# M462 register map
File version: 0.1
TOSHIBA Cortex-M3 MCU
Registers are 32-bit, read-write, reset 0x0 unless marked. A register's access mark holds for its fields unless they carry their own. Offsets are from the block's base; lines under a group give offsets from that group; [hi:lo] are bit positions; {n}, {i} and the like mark numbered series; 'fields as' and 'values as' point back to an identical list; <NAME> marks a mode.

## Memory map
0x40040000 SSP0 size 0x28 — Synchronous Serial Port
0x40041000 SSP1 size 0x28
0x40042000 SSP2 size 0x28
0x40048000 UART0 blocks up to offset 0x4C — UART
0x40049000 UART1 blocks up to offset 0x4C
0x4004C000 DMAA blocks up to offset 0x50 — DMA Controller
0x4004D000 DMAB blocks up to offset 0x50
0x4004E000 DMAC blocks up to offset 0x50
0x40050000 AD blocks up to offset 0x78 — 12bit A_D Converter
0x4005C000 EXB blocks up to offset 0x64 — External Bus Interface(EXB)
0x4005F000 DMAIF size 0xC — DMA Controller
0x40066000 ADILV blocks up to offset 0x24 — ADC infterface Register
0x400A0000 I2C0 size 0x1C — I2C Bus Interface (I2C)
0x400A1000 I2C1 size 0x1C
0x400A2000 I2C2 size 0x1C
0x400A3000 I2C3 size 0x1C
0x400A4000 I2C4 size 0x1C
0x400C4000 TB0 size 0x30 — 16-bit Timer_Event Counter (TB)
0x400C4100 TB1 size 0x30
0x400C4200 TB2 size 0x30
0x400C4300 TB3 size 0x30
0x400C4400 TB4 size 0x30
0x400C4500 TB5 size 0x30
0x400C4600 TB6 size 0x30
0x400C4700 TB7 size 0x30
0x400E1000 SC0 size 0x34 — Serial Channel (SC)
0x400E1100 SC1 size 0x34
0x400E1200 SC2 size 0x34
0x400E1600 SC6 size 0x34
0x400E1700 SC7 size 0x34
0x401C4800 TB8 size 0x30
0x401C4900 TB9 size 0x30
0x401C4A00 TBA size 0x30
0x401C4B00 TBB size 0x30
0x401C4C00 TBC size 0x30
0x401C4D00 TBD size 0x30
0x401C4E00 TBE size 0x30
0x401C4F00 TBF size 0x30
0x401E1300 SC3 size 0x34
0x401E1400 SC4 size 0x34
0x401E1500 SC5 size 0x34
0x401E1800 SC8 size 0x34
0x401E1900 SC9 size 0x34
0x402C0000 PA blocks up to offset 0x3C — Port A
0x402C0100 PB blocks up to offset 0x3C — Port B
0x402C0200 PC blocks up to offset 0x3C — Port C
0x402C0300 PD blocks up to offset 0x3C — Port D
0x402C0400 PE blocks up to offset 0x3C — Port E
0x402C0500 PF blocks up to offset 0x3C — Port F
0x402C0600 PG blocks up to offset 0x3C — Port G
0x402C0700 PH blocks up to offset 0x3C — Port H
0x402C0800 PJ blocks up to offset 0x3C — Port J
0x402C0900 PK blocks up to offset 0x3C — Port K
0x402C0A00 PL blocks up to offset 0x3C — Port L
0x402C0B00 PM blocks up to offset 0x3C — Port M
0x402C0C00 PN blocks up to offset 0x3C — Port N
0x402C7000 MT0 size 0x5C — 16-bit Multi-Purpose Timer (MPT-TMR_IGBT)
0x402C7100 MT1 size 0x5C
0x402F1000 OFD size 0x24 — Oscillation Frequency Detector (OFD)
0x402F2000 WD size 0x8 — Watchdog Timer (WD)
0x403CC000 RTC blocks up to offset 0x12 — Real Time Clock (RTC)
0x403E6000 CEC size 0x38 — Consumer Electronics Control (CEC)
0x403E7000 RMC0 size 0x38 — Remote Control Signal Preprocessor (RMC)
0x403E7100 RMC1 size 0x38
0x403F3000 CG blocks up to offset 0x6C — Clock Generator (CG)
0x403F4000 LVD size 0x8 — Low voltage detecter
0x41FFF000 FC blocks up to offset 0x15C — Flash Control (FC)

## SSP0 — Synchronous Serial Port
Base 0x40040000
Same registers: SSP1 0x40041000, SSP2 0x40042000
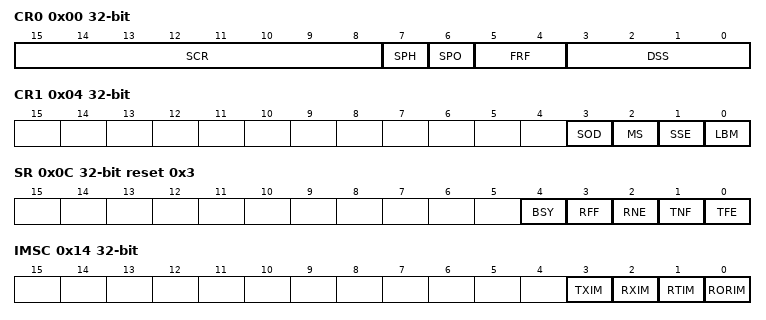
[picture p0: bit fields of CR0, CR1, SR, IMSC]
0x00 CR0 — SSP Control Register 0
  [15:8] SCR, [7] SPH, [6] SPO, [5:4] FRF, [3:0] DSS
0x04 CR1 — SSP Control Register 1
  [3] SOD, [2] MS, [1] SSE, [0] LBM
0x08 DR — SSP Data Register
  [15:0] DATA
0x0C SR ro reset 0x3 — SSP Status Register
  [4] BSY, [3] RFF, [2] RNE, [1] TNF, [0] TFE
0x10 CPSR — SSP Clock Prescaler Register
  [7:0] CPSDVSR
0x14 IMSC — SSP Interrupt Mask Set and Clear Register
  [3] TXIM, [2] RXIM, [1] RTIM, [0] RORIM
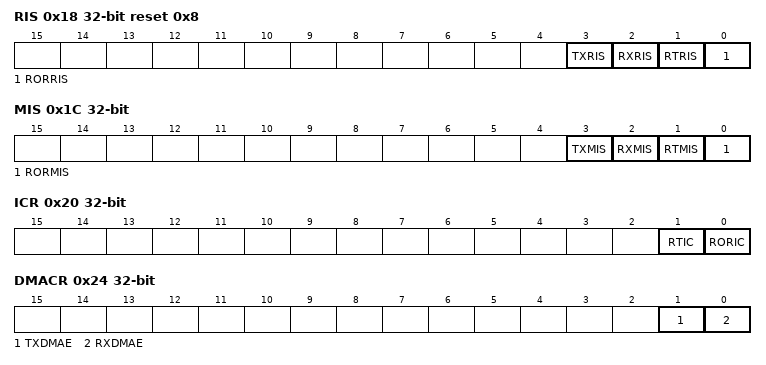
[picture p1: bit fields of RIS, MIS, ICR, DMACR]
0x18 RIS ro reset 0x8 — SSP Raw Interrupt Status Register
  [3] TXRIS, [2] RXRIS, [1] RTRIS, [0] RORRIS
0x1C MIS ro — SSP Masked Interrupt Status Register
  [3] TXMIS, [2] RXMIS, [1] RTMIS, [0] RORMIS
0x20 ICR wo reset not defined — SSP Interrupt Clear Register
  [1] RTIC, [0] RORIC
0x24 DMACR — SSP DMA Control Register
  [1] TXDMAE, [0] RXDMAE
